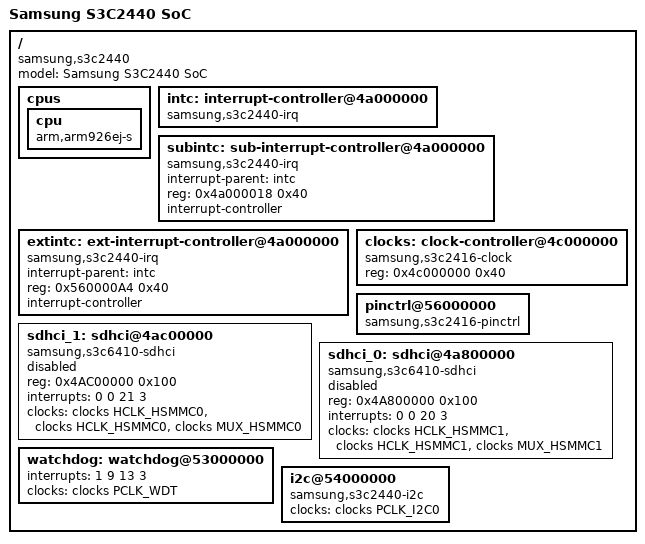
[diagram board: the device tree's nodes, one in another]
// SPDX-License-Identifier: GPL-2.0
/*
 * Samsung's S3C2416 SoC device tree source
 *
 * Copyright (c) 2013 Heiko Stuebner <heiko@sntech.de>
 */

#include "s3c2443.h"
#include "s3c24xx.dtsi"
#include "s3c2416-pinctrl.dtsi"

/ {
	model = "Samsung S3C2440 SoC";
	compatible = "samsung,s3c2440";

	cpus {
		cpu {
			compatible = "arm,arm926ej-s";
		};
	};
	/*first interrupt-controller */
	intc:interrupt-controller@4a000000 {
		compatible = "samsung,s3c2440-irq";
	};
	/*second interrupt-controller */
	subintc:sub-interrupt-controller@4a000000 {
		compatible = "samsung,s3c2440-irq";
		interrupt-parent = <&intc>;
		reg = <0x4a000018 0x40>;
		#interrupt-cells = <4>;
		interrupt-controller;
	};
	/*thrid interrupt-controller */
	extintc:ext-interrupt-controller@4a000000 {
		compatible = "samsung,s3c2440-irq";
		interrupt-parent = <&intc>;
		reg = <0x560000A4 0x40>;
		#interrupt-cells = <4>;
		interrupt-controller;
	};

	clocks: clock-controller@4c000000 {
		compatible = "samsung,s3c2416-clock";
		reg = <0x4c000000 0x40>;
		#clock-cells = <1>;
	};

	pinctrl@56000000 {
		compatible = "samsung,s3c2416-pinctrl";
	};
	sdhci_1: sdhci@4ac00000 {
		compatible = "samsung,s3c6410-sdhci";
		reg = <0x4AC00000 0x100>;
		interrupts = <0 0 21 3>;
		clock-names = "hsmmc", "mmc_busclk.0",
				"mmc_busclk.2";
		clocks = <&clocks HCLK_HSMMC0>, <&clocks HCLK_HSMMC0>,
				<&clocks MUX_HSMMC0>;
		status = "disabled";
	};

	sdhci_0: sdhci@4a800000 {
		compatible = "samsung,s3c6410-sdhci";
		reg = <0x4A800000 0x100>;
		interrupts = <0 0 20 3>;
		clock-names = "hsmmc", "mmc_busclk.0",
				"mmc_busclk.2";
		clocks = <&clocks HCLK_HSMMC1>, <&clocks HCLK_HSMMC1>,
				<&clocks MUX_HSMMC1>;
		status = "disabled";
	};

	watchdog: watchdog@53000000 {
		interrupts = <1 9 13 3>;
		clocks = <&clocks PCLK_WDT>;
		clock-names = "watchdog";
	};

	/*rtc: rtc@57000000 {
		compatible = "samsung,s3c2416-rtc";
		clocks = <&clocks PCLK_RTC>;
		clock-names = "rtc";
	};*/

	i2c@54000000 {
		compatible = "samsung,s3c2440-i2c";
		clocks = <&clocks PCLK_I2C0>;
		clock-names = "i2c";
	};
};
